AUTOSAR XML (schema 4-2-2)
package /Company/Components
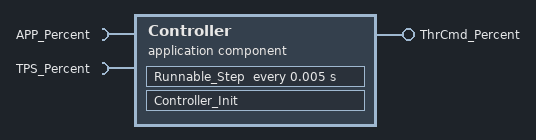
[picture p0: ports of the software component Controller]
  application sw component type Controller
    require port APP_Percent: nonqueued-receiver-com-spec{data-element=Value, init-value=ComSpec5dda77b1_45067123718c10a8:0}, required-interface=APP_Percent
    require port TPS_Percent: nonqueued-receiver-com-spec{data-element=Value, init-value=ComSpec4815be1b_709ecd5140c8e072:0}, required-interface=TPS_Percent
    provide port ThrCmd_Percent: nonqueued-sender-com-spec{data-element=Value, init-value=ComSpec69f9a89c_3c720dba22b02499:0}, provided-interface=ThrCmd_Percent
    behavior Controller_InternalBehavior: handle-termination-and-restart=NO-SUPPORT
      init event Controller_InitEvent: start-on-event=Controller_Init
      timing event Event_Runnable_Step: start-on-event=Runnable_Step, period=0.005
      runnable Controller_Init
      runnable Runnable_Step
        data-read-access:
          access IN_APP_Percent_Value: accessed-variable=APP_Percent.Value
          access IN_TPS_Percent_Value: accessed-variable=TPS_Percent.Value
        data-write-access:
          access OUT_ThrCmd_Percent_Value: accessed-variable=ThrCmd_Percent.Value
